VERSION ""

NS_ :

BS_:

BU_: DBG

BO_ 123 MotorController_Status1: 8 Vector__XXX
 SG_ Fault_MC_ERR15 : 63|1@1+ (1,0) [0|0] "" Vector__XXX
 SG_ Fault_MC_ERR14 : 62|1@1+ (1,0) [0|0] "" Vector__XXX
 SG_ Fault_MC_ERR13 : 61|1@1+ (1,0) [0|0] "" Vector__XXX
 SG_ Fault_MC_ERR12 : 60|1@1+ (1,0) [0|0] "" Vector__XXX
 SG_ Fault_MC_ERR11 : 59|1@1+ (1,0) [0|0] "" Vector__XXX
 SG_ Fault_MC_ERR10 : 58|1@1+ (1,0) [0|0] "" Vector__XXX
 SG_ Fault_MC_ERR9 : 57|1@1+ (1,0) [0|0] "" Vector__XXX
 SG_ Fault_MC_ERR8 : 56|1@1+ (1,0) [0|0] "" Vector__XXX
 SG_ Fault_MC_ERR7 : 55|1@1+ (1,0) [0|0] "" Vector__XXX
 SG_ Fault_MC_ERR6 : 54|1@1+ (1,0) [0|0] "" Vector__XXX
 SG_ Fault_MC_ERR5 : 53|1@1+ (1,0) [0|0] "" Vector__XXX
 SG_ Fault_MC_ERR4 : 52|1@1+ (1,0) [0|0] "" Vector__XXX
 SG_ Fault_MC_ERR3 : 51|1@1+ (1,0) [0|0] "" Vector__XXX
 SG_ Fault_MC_ERR2 : 50|1@1+ (1,0) [0|0] "" Vector__XXX
 SG_ Fault_MC_ERR1 : 49|1@1+ (1,0) [0|0] "" Vector__XXX
 SG_ Fault_MC_ERR0 : 48|1@1+ (1,0) [0|0] "" Vector__XXX
 SG_ Battery_Voltage_V : 32|16@1+ (0.1,0) [0|180] "V" Vector__XXX
 SG_ Actual_Current_A : 16|16@1+ (0.1,0) [0|400] "A" Vector__XXX
 SG_ Actual_Speed_RPM : 0|16@1+ (1.0,0) [0|6000] "rpm" Vector__XXX

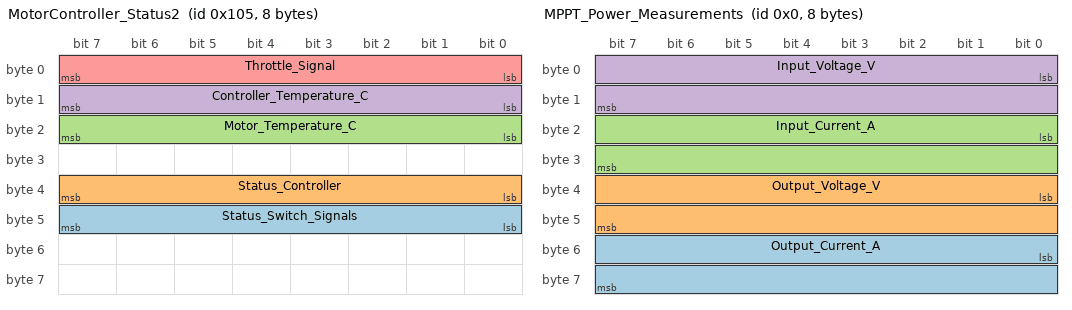
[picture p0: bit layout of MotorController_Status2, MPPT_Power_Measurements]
BO_ 261 MotorController_Status2: 8 Vector__XXX
 SG_ Status_Switch_Signals : 40|8@1+ (1,0) [0|0] "" Vector__XXX
 SG_ Status_Controller : 32|8@1+ (1,0) [0|0] "" Vector__XXX
 SG_ Motor_Temperature_C : 16|8@1- (1.0,-30) [-30|225] "�C" Vector__XXX
 SG_ Controller_Temperature_C : 8|8@1- (1.0,-40) [-40|215] "�C" Vector__XXX
 SG_ Throttle_Signal : 0|8@1+ (0.0196,0) [0|5] "V" Vector__XXX

BO_ 0 MPPT_Power_Measurements: 8 Vector__XXX
 SG_ Output_Current_A : 48|16@1- (0.0005,0) [-16.0|16.0] "A" Vector__XXX
 SG_ Output_Voltage_V : 32|16@1- (0.01,0) [-327.0|327.0] "V" Vector__XXX
 SG_ Input_Current_A : 16|16@1- (0.0005,0) [-16.0|16.0] "A" Vector__XXX
 SG_ Input_Voltage_V : 0|16@1- (0.01,0) [-327.0|327.0] "V" Vector__XXX

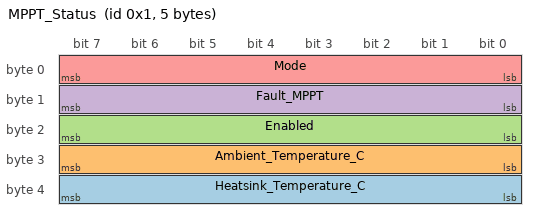
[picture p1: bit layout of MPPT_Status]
BO_ 1 MPPT_Status: 5 Vector__XXX
 SG_ Heatsink_Temperature_C : 32|8@1- (1,0) [-128|127] "�C" Vector__XXX
 SG_ Ambient_Temperature_C : 24|8@1- (1,0) [-128|127] "�C" Vector__XXX
 SG_ Enabled : 16|8@1+ (1,0) [0|0] "" Vector__XXX
 SG_ Fault_MPPT : 8|8@1+ (1,0) [0|0] "" Vector__XXX
 SG_ Mode : 0|8@1+ (1,0) [0|0] "" Vector__XXX

BA_DEF_ BO_  "GenMsgCycleTime" INT 0 65535;
BA_DEF_DEF_  "GenMsgCycleTime" 0;
BA_ "GenMsgCycleTime" BO_ 123 50;
BA_ "GenMsgCycleTime" BO_ 261 50;
BA_ "GenMsgCycleTime" BO_ 0 500;
BA_ "GenMsgCycleTime" BO_ 1 1000;
VAL_ 123 Fault_MC_ERR15 0 "OK" 1 "Hall Galvanometer sensor" ;
VAL_ 123 Fault_MC_ERR14 0 "OK" 1 "Motor over-temperature" ;
VAL_ 123 Fault_MC_ERR13 0 "OK" 1 "Reserved" ;
VAL_ 123 Fault_MC_ERR12 0 "OK" 1 "Reserved" ;
VAL_ 123 Fault_MC_ERR11 0 "OK" 1 "Angle sensor error" ;
VAL_ 123 Fault_MC_ERR10 0 "OK" 1 "Hall throttle is open or short-circuit" ;
VAL_ 123 Fault_MC_ERR9 0 "OK" 1 "Internal reset" ;
VAL_ 123 Fault_MC_ERR8 0 "OK" 1 "Reserved" ;
VAL_ 123 Fault_MC_ERR7 0 "OK" 1 "Throttle error at power-up" ;
VAL_ 123 Fault_MC_ERR6 0 "OK" 1 "Over temperature" ;
VAL_ 123 Fault_MC_ERR5 0 "OK" 1 "Internal volts fault " ;
VAL_ 123 Fault_MC_ERR4 0 "OK" 1 "Stall" ;
VAL_ 123 Fault_MC_ERR3 0 "OK" 1 "Reserved" ;
VAL_ 123 Fault_MC_ERR2 0 "OK" 1 "Low voltage" ;
VAL_ 123 Fault_MC_ERR1 0 "OK" 1 "Over voltage" ;
VAL_ 123 Fault_MC_ERR0 0 "OK" 1 "Identification error" ;
VAL_ 1 Fault_MPPT 0 "OK" 1 "Configuration Error" 2 "Input Over Voltage" 3 "Output Over Voltage" 4 "Output Over Current" 5 "Input Over Current" 6 "Input Under Current" 7 "Phase Over Current" 8 "General Fault" ;
